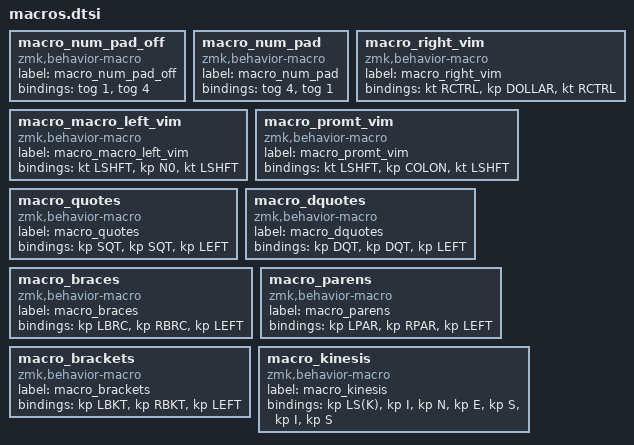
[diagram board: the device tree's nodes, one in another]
macro_num_pad_off: macro_num_pad_off{
compatible = "zmk,behavior-macro";
label = "macro_num_pad_off";
#binding-cells = <0>;
bindings = <&tog 1>, <&tog 4>;
};
macro_num_pad: macro_num_pad{
compatible = "zmk,behavior-macro";
label = "macro_num_pad";
#binding-cells = <0>;
bindings = <&tog 4>, <&tog 1>;
};
macro_right_vim: macro_right_vim{
compatible = "zmk,behavior-macro";
label = "macro_right_vim";
#binding-cells = <0>;
bindings = <&kt RCTRL>, <&kp DOLLAR>, <&kt RCTRL>;
};
macro_macro_left_vim: macro_macro_left_vim{
compatible = "zmk,behavior-macro";
label = "macro_macro_left_vim";
#binding-cells = <0>;
bindings = <&kt LSHFT>, <&kp N0>, <&kt LSHFT>;
};
macro_promt_vim: macro_promt_vim{
compatible = "zmk,behavior-macro";
label = "macro_promt_vim";
#binding-cells = <0>;
bindings = <&kt LSHFT>, <&kp COLON>, <&kt LSHFT>;
};
macro_quotes: macro_quotes {
    compatible = "zmk,behavior-macro";
    label = "macro_quotes";
    #binding-cells = <0>;
    bindings = <&kp SQT>, <&kp SQT>, <&kp LEFT>;
  };
  macro_dquotes: macro_dquotes {
    compatible = "zmk,behavior-macro";
    label = "macro_dquotes";
    #binding-cells = <0>;
    bindings = <&kp DQT>, <&kp DQT>, <&kp LEFT>;
  };
  macro_braces: macro_braces {
    compatible = "zmk,behavior-macro";
    label = "macro_braces";
    #binding-cells = <0>;
    bindings = <&kp LBRC>, <&kp RBRC>, <&kp LEFT>;
  };
  macro_parens: macro_parens {
    compatible = "zmk,behavior-macro";
    label = "macro_parens";
    #binding-cells = <0>;
    bindings = <&kp LPAR>, <&kp RPAR>, <&kp LEFT>;
  };
  macro_brackets: macro_brackets {
    compatible = "zmk,behavior-macro";
    label = "macro_brackets";
    #binding-cells = <0>;
    bindings = <&kp LBKT>, <&kp RBKT>, <&kp LEFT>;
  };
  macro_kinesis: macro_kinesis {
    compatible = "zmk,behavior-macro";
    label = "macro_kinesis";
    #binding-cells = <0>;
    bindings = <&kp LS(K)>, <&kp I>, <&kp N>, <&kp E>, <&kp S>, <&kp I>, <&kp S>;
  };
